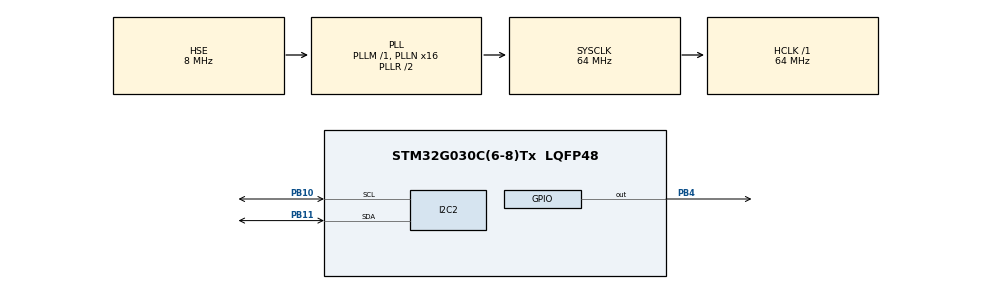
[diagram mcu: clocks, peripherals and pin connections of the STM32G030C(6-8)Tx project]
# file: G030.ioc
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I2C2.Timing=0x10707DBC
Mcu.Family=STM32G0
Mcu.Name=STM32G030C(6-8)Tx
Mcu.Package=LQFP48
PA13.Mode=Serial_Wire
PA13.Signal=SYS_SWDIO
PA14-BOOT0.Mode=Serial_Wire
PA14-BOOT0.Signal=SYS_SWCLK
PB10.Mode=I2C
PB10.Signal=I2C2_SCL
PB11.Mode=I2C
PB11.Signal=I2C2_SDA
PB4.Signal=GPIO_Output
PF0-OSC_IN\ (PF0).Mode=HSE-External-Oscillator
PF0-OSC_IN\ (PF0).Signal=RCC_OSC_IN
PF1-OSC_OUT\ (PF1).Mode=HSE-External-Oscillator
PF1-OSC_OUT\ (PF1).Signal=RCC_OSC_OUT
ProjectManager.HeapSize=0x200
ProjectManager.StackSize=0x400
ProjectManager.TargetToolchain=MDK-ARM V5.32
RCC.ADCFreq_Value=64000000
RCC.AHBFreq_Value=64000000
RCC.CortexFreq_Value=64000000
RCC.EXTERNAL_CLOCK_VALUE=12288000
RCC.HCLKFreq_Value=64000000
RCC.HSE_VALUE=8000000
RCC.HSI_VALUE=16000000
RCC.LSE_VALUE=32768
RCC.PLLN=16
RCC.PLLSourceVirtual=RCC_PLLSOURCE_HSE
RCC.SYSCLKFreq_VALUE=64000000
RCC.SYSCLKSource=RCC_SYSCLKSOURCE_PLLCLK
RCC.VCOOutputFreq_Value=128000000
board=custom

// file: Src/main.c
/* USER CODE BEGIN Header */

/* USER CODE END Header */

#include "main.h"
#include "i2c.h"
#include "gpio.h"

void SystemClock_Config(void);
/* USER CODE BEGIN PFP */
extern void EE_IIC_Init(void);
extern uint8_t EE_EE_IIC_SendByteToSlave(uint8_t I2C_Addr,uint8_t reg,uint8_t data);
extern uint8_t EE_IIC_ReadByteFromSlave(uint8_t I2C_Addr,uint8_t reg,uint8_t *buf);
/* USER CODE END PFP */

/* USER CODE BEGIN 0 */
void I2C_Test(void);
unsigned char EEDATA;
/* USER CODE END 0 */

int main(void)
{

  /* MCU Configuration--------------------------------------------------------*/

  /* Reset of all peripherals, Initializes the Flash interface and the Systick. */
  HAL_Init();

  /* Configure the system clock */
  SystemClock_Config();

  /* Initialize all configured peripherals */
  MX_GPIO_Init();
  MX_I2C2_Init();
  /* USER CODE BEGIN 2 */
EE_IIC_Init();
EE_EE_IIC_SendByteToSlave(0xA0,0x00,0x33);
HAL_Delay(10);
EE_IIC_ReadByteFromSlave(0xA0,0x00,&EEDATA);
  /* USER CODE END 2 */

  /* Infinite loop */
  while (1)
  {

  }
}

void SystemClock_Config(void)
{
  RCC_OscInitTypeDef RCC_OscInitStruct = {0};
  RCC_ClkInitTypeDef RCC_ClkInitStruct = {0};

  /** Configure the main internal regulator output voltage
  */
  HAL_PWREx_ControlVoltageScaling(PWR_REGULATOR_VOLTAGE_SCALE1);
  /** Initializes the CPU, AHB and APB busses clocks
  */
  RCC_OscInitStruct.OscillatorType = RCC_OSCILLATORTYPE_HSE;
  RCC_OscInitStruct.HSEState = RCC_HSE_ON;
  RCC_OscInitStruct.PLL.PLLState = RCC_PLL_ON;
  RCC_OscInitStruct.PLL.PLLSource = RCC_PLLSOURCE_HSE;
  RCC_OscInitStruct.PLL.PLLM = RCC_PLLM_DIV1;
  RCC_OscInitStruct.PLL.PLLN = 16;
  RCC_OscInitStruct.PLL.PLLP = RCC_PLLP_DIV2;
  RCC_OscInitStruct.PLL.PLLR = RCC_PLLR_DIV2;
  if (HAL_RCC_OscConfig(&RCC_OscInitStruct) != HAL_OK)
  {
    Error_Handler();
  }
  /** Initializes the CPU, AHB and APB busses clocks
  */
  RCC_ClkInitStruct.ClockType = RCC_CLOCKTYPE_HCLK|RCC_CLOCKTYPE_SYSCLK
                              |RCC_CLOCKTYPE_PCLK1;
  RCC_ClkInitStruct.SYSCLKSource = RCC_SYSCLKSOURCE_PLLCLK;
  RCC_ClkInitStruct.AHBCLKDivider = RCC_SYSCLK_DIV1;
  RCC_ClkInitStruct.APB1CLKDivider = RCC_HCLK_DIV1;

  if (HAL_RCC_ClockConfig(&RCC_ClkInitStruct, FLASH_LATENCY_2) != HAL_OK)
  {
    Error_Handler();
  }
}

void Error_Handler(void)
{
}

/************************ (C) COPYRIGHT STMicroelectronics *****END OF FILE****/
